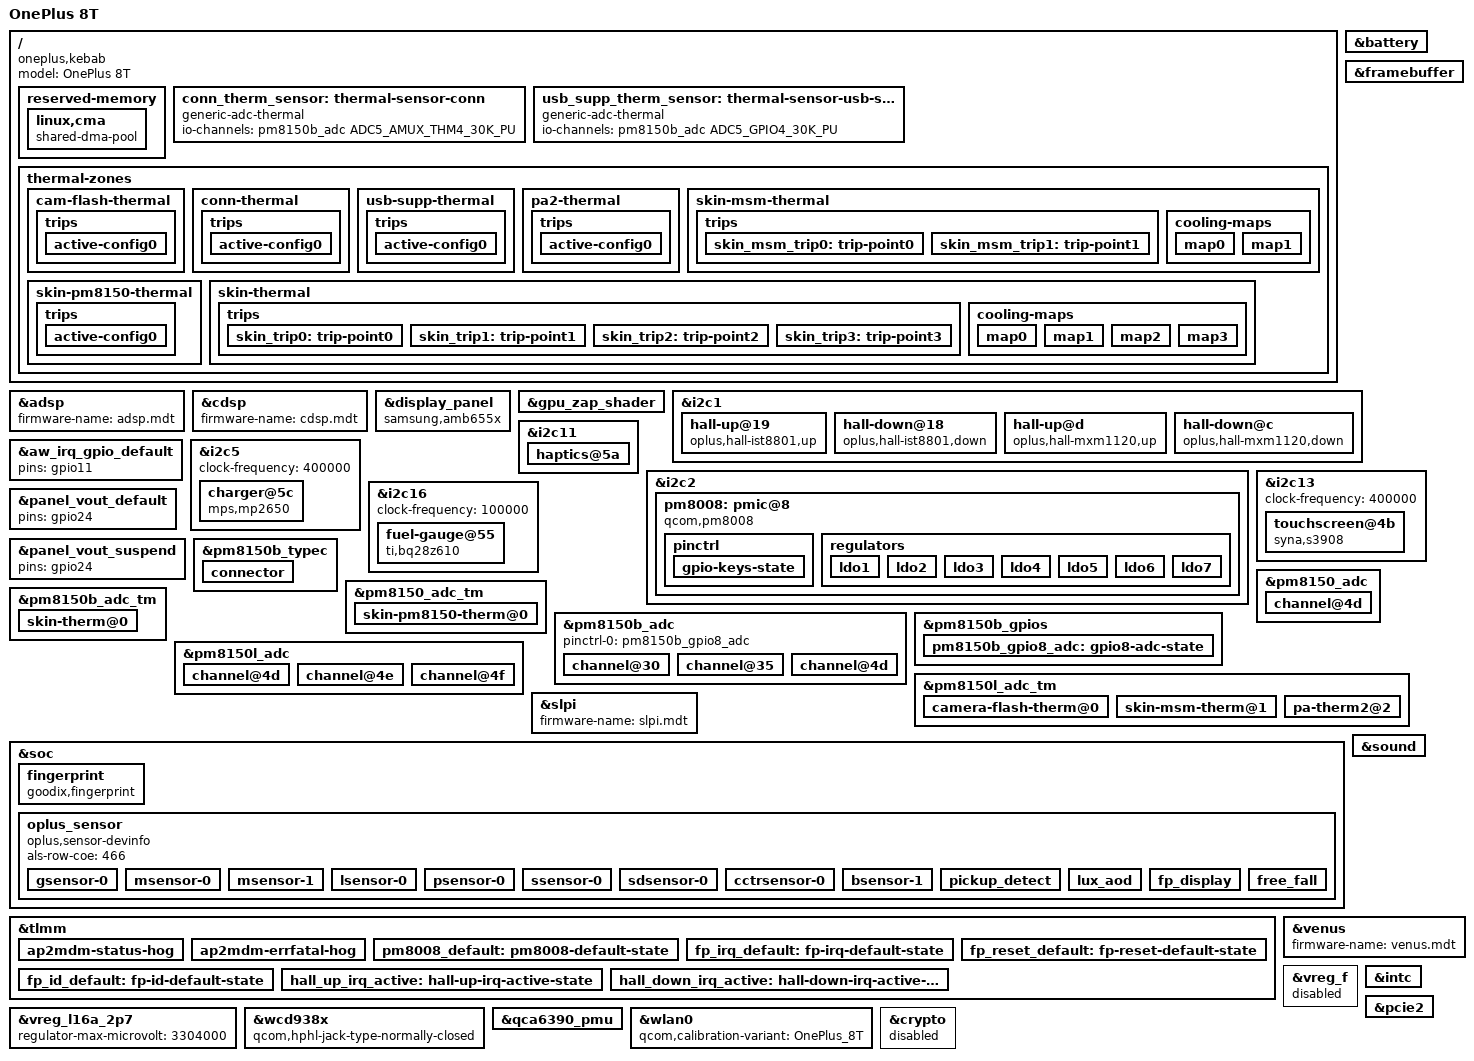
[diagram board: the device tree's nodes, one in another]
// SPDX-License-Identifier: GPL-2.0 OR BSD-3-Clause
/*
 * Copyright (c) 2026, The Linux Foundation.
 */

#include "sm8250-oneplus-common.dtsi"

/ {
	model = "OnePlus 8T";
	compatible = "oneplus,kebab", "qcom,sm8250", "qcom,kona";

	reserved-memory {
		/*
		 * Default CMA area for QTEE trusted app images and shared buffers.
		 * Keep below 4 GiB so legacy 32-bit QSEECom TAs (e.g. Goodix FP)
		 * can embed physical addresses with is64 = 0.
		 */
		linux,cma {
			compatible = "shared-dma-pool";
			alloc-ranges = <0x0 0x80000000 0x0 0x80000000>;
			size = <0x0 0x10000000>;
			reusable;
			linux,cma-default;
		};
	};

	conn_therm_sensor: thermal-sensor-conn {
		compatible = "generic-adc-thermal";
		#thermal-sensor-cells = <0>;
		io-channels = <&pm8150b_adc ADC5_AMUX_THM4_30K_PU>;
		io-channel-names = "sensor-channel";
	};

	usb_supp_therm_sensor: thermal-sensor-usb-supp {
		compatible = "generic-adc-thermal";
		#thermal-sensor-cells = <0>;
		io-channels = <&pm8150b_adc ADC5_GPIO4_30K_PU>;
		io-channel-names = "sensor-channel";
	};

	thermal-zones {
		cam-flash-thermal {
			polling-delay-passive = <0>;
			polling-delay = <0>;
			thermal-sensors = <&pm8150l_adc_tm 0>;

			trips {
				active-config0 {
					temperature = <125000>;
					hysteresis = <1000>;
					type = "passive";
				};
			};
		};

		conn-thermal {
			polling-delay-passive = <0>;
			polling-delay = <0>;
			thermal-sensors = <&conn_therm_sensor>;

			trips {
				active-config0 {
					temperature = <125000>;
					hysteresis = <1000>;
					type = "passive";
				};
			};
		};

		usb-supp-thermal {
			polling-delay-passive = <0>;
			polling-delay = <0>;
			thermal-sensors = <&usb_supp_therm_sensor>;

			trips {
				active-config0 {
					temperature = <125000>;
					hysteresis = <1000>;
					type = "passive";
				};
			};
		};

		pa2-thermal {
			polling-delay-passive = <0>;
			polling-delay = <0>;
			thermal-sensors = <&pm8150l_adc_tm 2>;

			trips {
				active-config0 {
					temperature = <125000>;
					hysteresis = <1000>;
					type = "passive";
				};
			};
		};

		skin-msm-thermal {
			polling-delay-passive = <1000>;
			polling-delay = <0>;
			thermal-sensors = <&pm8150l_adc_tm 1>;

			trips {
				skin_msm_trip0: trip-point0 {
					temperature = <63000>;
					hysteresis = <2000>;
					type = "passive";
				};

				skin_msm_trip1: trip-point1 {
					temperature = <65000>;
					hysteresis = <2000>;
					type = "passive";
				};
			};

			cooling-maps {
				map0 {
					trip = <&skin_msm_trip0>;
					cooling-device = <&gpu 2 2>,
							 <&cpu0 2 2>,
							 <&cpu4 7 7>,
							 <&cpu7 8 8>;
				};

				map1 {
					trip = <&skin_msm_trip1>;
					cooling-device = <&gpu 3 3>,
							 <&cpu0 3 3>,
							 <&cpu4 9 9>,
							 <&cpu7 12 12>;
				};
			};
		};

		skin-pm8150-thermal {
			polling-delay-passive = <0>;
			polling-delay = <0>;
			thermal-sensors = <&pm8150_adc_tm 0>;

			trips {
				active-config0 {
					temperature = <125000>;
					hysteresis = <1000>;
					type = "passive";
				};
			};
		};

		skin-thermal {
			polling-delay-passive = <1000>;
			polling-delay = <0>;
			thermal-sensors = <&pm8150b_adc_tm 0>;

			trips {
				skin_trip0: trip-point0 {
					temperature = <48000>;
					hysteresis = <2000>;
					type = "passive";
				};

				skin_trip1: trip-point1 {
					temperature = <49000>;
					hysteresis = <1000>;
					type = "passive";
				};

				skin_trip2: trip-point2 {
					temperature = <50000>;
					hysteresis = <1000>;
					type = "passive";
				};

				skin_trip3: trip-point3 {
					temperature = <52000>;
					hysteresis = <2000>;
					type = "passive";
				};
			};

			cooling-maps {
				map0 {
					trip = <&skin_trip0>;
					cooling-device = <&gpu 2 2>,
							 <&cpu4 7 7>,
							 <&cpu7 8 8>;
				};

				map1 {
					trip = <&skin_trip1>;
					cooling-device = <&cpu4 9 9>,
							 <&cpu7 11 11>;
				};

				map2 {
					trip = <&skin_trip2>;
					cooling-device = <&gpu 4 4>,
							 <&cpu0 3 3>,
							 <&cpu4 14 14>,
							 <&cpu7 15 15>;
				};

				map3 {
					trip = <&skin_trip3>;
					cooling-device = <&gpu 5 5>,
							 <&cpu0 10 10>,
							 <&cpu4 16 16>,
							 <&cpu7 18 18>;
				};
			};
		};
	};
};

&adsp {
	firmware-name = "adsp.mdt";

	status = "okay";
};

&battery {
	/* Dual-cell 2S pack (2x 2250 mAh in series, 8.70 V max, 19.575 Wh) */
	charge-full-design-microamp-hours = <2250000>;
	energy-full-design-microwatt-hours = <19575000>;
	voltage-max-design-microvolt = <8700000>;
};

&cdsp {
	firmware-name = "cdsp.mdt";

	status = "okay";
};

&display_panel {
	compatible = "samsung,amb655x";

	width-mm = <70>;
	height-mm = <151>;

	status = "okay";
};

&framebuffer {
	width = <1080>;
	height = <2400>;
	stride = <(1080 * 4)>;
};

&gpu_zap_shader {
	firmware-name = "qcom/sm8250/OnePlus/kebab/a650_zap.mbn";
};

&i2c1 {
	/*
	 * Dual-Hall Alert Slider sensors: OnePlus 8T ships with either
	 * iSentek IST8801 (0x19/0x18) or MagnaChip MXM1120 (0x0d/0x0c).
	 * Pinctrl uses the non-default "active" state so only the populated
	 * pair claims the shared IRQ GPIOs after I2C DID verification.
	 */
	hall-up@19 {
		compatible = "oplus,hall-ist8801,up";
		reg = <0x19>;
		vdd-supply = <&vreg_l10c_3p0>;
		interrupts-extended = <&tlmm 157 IRQ_TYPE_LEVEL_LOW>;
		pinctrl-names = "active";
		pinctrl-0 = <&hall_up_irq_active>;
	};

	hall-down@18 {
		compatible = "oplus,hall-ist8801,down";
		reg = <0x18>;
		vdd-supply = <&vreg_l10c_3p0>;
		interrupts-extended = <&tlmm 138 IRQ_TYPE_LEVEL_LOW>;
		pinctrl-names = "active";
		pinctrl-0 = <&hall_down_irq_active>;
	};

	hall-up@d {
		compatible = "oplus,hall-mxm1120,up";
		reg = <0x0d>;
		vdd-supply = <&vreg_l10c_3p0>;
		interrupts-extended = <&tlmm 157 IRQ_TYPE_LEVEL_LOW>;
		pinctrl-names = "active";
		pinctrl-0 = <&hall_up_irq_active>;
	};

	hall-down@c {
		compatible = "oplus,hall-mxm1120,down";
		reg = <0x0c>;
		vdd-supply = <&vreg_l10c_3p0>;
		interrupts-extended = <&tlmm 138 IRQ_TYPE_LEVEL_LOW>;
		pinctrl-names = "active";
		pinctrl-0 = <&hall_down_irq_active>;
	};
};

&i2c11 {
	/* OnePlus 8T routes AW8697 IRQ to TLMM GPIO 11 (8/8 Pro use GPIO 118). */
	haptics@5a {
		interrupts-extended = <&tlmm 11 IRQ_TYPE_EDGE_FALLING>;
	};
};

&aw_irq_gpio_default {
	pins = "gpio11";
};

&i2c2 {
	pm8008: pmic@8 {
		compatible = "qcom,pm8008";
		reg = <0x8>;

		interrupt-parent = <&tlmm>;
		interrupts = <112 IRQ_TYPE_EDGE_RISING>;

		reset-gpios = <&tlmm 93 GPIO_ACTIVE_LOW>;

		vdd-l1-l2-supply = <&vreg_s8c_1p3>;
		vdd-l3-l4-supply = <&vreg_bob>;
		vdd-l5-supply = <&vreg_bob>;
		vdd-l6-supply = <&vreg_bob>;
		vdd-l7-supply = <&vreg_bob>;

		gpio-controller;
		#gpio-cells = <2>;
		gpio-ranges = <&pm8008 0 0 2>;

		interrupt-controller;
		#interrupt-cells = <2>;

		#thermal-sensor-cells = <0>;

		pinctrl {
			gpio-keys-state {
				pins = "gpio1";
				function = "normal";
			};
		};

		regulators {
			ldo1 {
				regulator-name = "vreg_l1p";
				regulator-min-microvolt = <528000>;
				regulator-max-microvolt = <1504000>;
			};

			ldo2 {
				regulator-name = "vreg_l2p";
				regulator-min-microvolt = <528000>;
				regulator-max-microvolt = <1300000>;
			};

			ldo3 {
				regulator-name = "vreg_l3p";
				regulator-min-microvolt = <1500000>;
				regulator-max-microvolt = <3400000>;
			};

			ldo4 {
				regulator-name = "vreg_l4p";
				regulator-min-microvolt = <1800000>;
				regulator-max-microvolt = <1800000>;
			};

			ldo5 {
				regulator-name = "vreg_l5p";
				regulator-min-microvolt = <1500000>;
				regulator-max-microvolt = <3400000>;
			};

			ldo6 {
				regulator-name = "vreg_l6p";
				regulator-min-microvolt = <1500000>;
				regulator-max-microvolt = <3400000>;
			};

			ldo7 {
				regulator-name = "vreg_l7p";
				regulator-min-microvolt = <1500000>;
				regulator-max-microvolt = <3400000>;
			};
		};
	};
};

&i2c5 {
	clock-frequency = <400000>;

	status = "okay";

	charger@5c {
		compatible = "mps,mp2650";
		reg = <0x5c>;
		monitored-battery = <&battery>;
		constant-charge-voltage-max-microvolt = <8700000>;
		constant-charge-current-max-microamp = <3000000>;
		input-current-limit-microamp = <3000000>;
		otg-enable-gpios = <&pm8150_gpios 3 GPIO_ACTIVE_HIGH>;
	};
};

&i2c13 {
	clock-frequency = <400000>;

	status = "okay";

	touchscreen@4b {
		compatible = "syna,s3908";
		reg = <0x4b>;
		interrupts-extended = <&tlmm 39 IRQ_TYPE_LEVEL_LOW>;
		reset-gpios = <&tlmm 38 GPIO_ACTIVE_LOW>;
		vdd-supply = <&vreg_l13a_ts_3p0>;
		vcc-supply = <&vreg_l1c_1p8>;
		touchscreen-size-x = <1080>;
		touchscreen-size-y = <2400>;
		pinctrl-0 = <&ts_int_default>;
		pinctrl-1 = <&ts_rst_suspend>;
		pinctrl-names = "default";
	};
};

&i2c16 {
	/* OOS runs this bus at 100 kHz; 400 kHz NAKs the gauge at 0x55 */
	clock-frequency = <100000>;

	status = "okay";

	fuel-gauge@55 {
		compatible = "ti,bq28z610";
		reg = <0x55>;
		monitored-battery = <&battery>;
	};
};

&panel_vout_default {
	pins = "gpio24";
};

&panel_vout_suspend {
	pins = "gpio24";
};

&pm8150b_typec {
	connector {
		op-sink-microwatt = <27000000>;
		sink-pdos = <PDO_FIXED(5000, 3000,
			     PDO_FIXED_DUAL_ROLE |
			     PDO_FIXED_USB_COMM |
			     PDO_FIXED_DATA_SWAP)>,
			    <PDO_FIXED(9000, 3000, 0)>;
	};
};

&pm8150_adc {
	channel@4d {
		reg = <ADC5_AMUX_THM1_100K_PU>;
		qcom,ratiometric;
		qcom,hw-settle-time = <200>;
		label = "skin_pm8150_therm";
	};
};

&pm8150_adc_tm {
	status = "okay";

	skin-pm8150-therm@0 {
		reg = <0>;
		io-channels = <&pm8150_adc ADC5_AMUX_THM1_100K_PU>;
		qcom,ratiometric;
		qcom,hw-settle-time-us = <200>;
	};
};

&pm8150b_adc {
	pinctrl-0 = <&pm8150b_gpio8_adc>;
	pinctrl-names = "default";

	channel@30 {
		reg = <ADC5_AMUX_THM4_30K_PU>;
		qcom,ratiometric;
		qcom,hw-settle-time = <700>;
		label = "usb_temp_adc";
	};

	channel@35 {
		reg = <ADC5_GPIO4_30K_PU>;
		qcom,ratiometric;
		qcom,hw-settle-time = <700>;
		label = "usb_supp_temp_adc";
	};

	channel@4d {
		reg = <ADC5_AMUX_THM1_100K_PU>;
		qcom,ratiometric;
		qcom,hw-settle-time = <200>;
		label = "skin_therm";
	};
};

&pm8150b_adc_tm {
	status = "okay";

	skin-therm@0 {
		reg = <0>;
		io-channels = <&pm8150b_adc ADC5_AMUX_THM1_100K_PU>;
		qcom,ratiometric;
		qcom,hw-settle-time-us = <200>;
	};
};

&pm8150b_gpios {
	pm8150b_gpio8_adc: gpio8-adc-state {
		pins = "gpio8";
		function = "normal";
		bias-high-impedance;
	};
};

&pm8150l_adc {
	channel@4d {
		reg = <ADC5_AMUX_THM1_100K_PU>;
		qcom,ratiometric;
		qcom,hw-settle-time = <200>;
		label = "camera_flash_therm";
	};

	channel@4e {
		reg = <ADC5_AMUX_THM2_100K_PU>;
		qcom,ratiometric;
		qcom,hw-settle-time = <200>;
		label = "skin_msm_therm";
	};

	channel@4f {
		reg = <ADC5_AMUX_THM3_100K_PU>;
		qcom,ratiometric;
		qcom,hw-settle-time = <200>;
		label = "pa_therm2";
	};
};

&pm8150l_adc_tm {
	status = "okay";

	camera-flash-therm@0 {
		reg = <0>;
		io-channels = <&pm8150l_adc ADC5_AMUX_THM1_100K_PU>;
		qcom,ratiometric;
		qcom,hw-settle-time-us = <200>;
	};

	skin-msm-therm@1 {
		reg = <1>;
		io-channels = <&pm8150l_adc ADC5_AMUX_THM2_100K_PU>;
		qcom,ratiometric;
		qcom,hw-settle-time-us = <200>;
	};

	pa-therm2@2 {
		reg = <2>;
		io-channels = <&pm8150l_adc ADC5_AMUX_THM3_100K_PU>;
		qcom,ratiometric;
		qcom,hw-settle-time-us = <200>;
	};
};

&slpi {
	firmware-name = "slpi.mdt";

	status = "okay";
};

&soc {
	fingerprint {
		compatible = "goodix,fingerprint";
		fp-gpio-irq = <&tlmm 23 GPIO_ACTIVE_HIGH>;
		fp-gpio-reset = <&tlmm 68 GPIO_ACTIVE_HIGH>;
		fp-gpio-id = <&tlmm 77 GPIO_ACTIVE_HIGH>;
		vdd-supply = <&vreg_l16a_2p7>;
		vdd-min-uv = <3304000>;
		vdd-max-uv = <3304000>;
		pinctrl-0 = <&fp_irq_default>, <&fp_reset_default>, <&fp_id_default>;
		pinctrl-names = "default";
	};

	oplus_sensor {
		compatible = "oplus,sensor-devinfo";
		als-row-coe = <466>;

		gsensor-0 {
			sensor-name = <0x8>; /* BMI260 */
			sensor-direction = <4>;
			sensor-index = <0>;
			sensor-type = <0>; /* OPLUS_ACCEL */
		};

		msensor-0 {
			sensor-name = <0x1>; /* AKM0991X */
			sensor-direction = <4>;
			sensor-index = <0>;
			sensor-type = <2>; /* OPLUS_MAG */
			parameter-number = <18>;
			soft-mag-parameter = <10000 0 0 0 0 0 0 0 10000 0 0 0 0 0 0 0 10000 0>;
		};

		msensor-1 {
			sensor-name = <0x2>; /* MMC5603 */
			sensor-direction = <1>;
			sensor-index = <1>;
			sensor-type = <2>; /* OPLUS_MAG */
			parameter-number = <18>;
			soft-mag-parameter = <9941 0 1024 0 356 0 137 0 9375 0 608 0 102 0 495 0 11471 0>;
		};

		lsensor-0 {
			sensor-name = <0x01>; /* STK33502 */
			sensor-index = <0>;
			sensor-type = <3>; /* OPLUS_LIGHT */
			bus-number = <5>;
			irq-number = <136>;
			als-type = <2>;
			is-unit-device = <1>;
			is-als-dri = <0>;
			als-factor = <466>;
			is_als_initialed = <0>;
			als_buffer_length = <10>;
		};

		psensor-0 {
			sensor-name = <0x1>; /* STK33502 */
			sensor-index = <0>;
			sensor-type = <4>; /* OPLUS_PROXIMITY */
			bus-number = <5>;
			irq-number = <136>;
			ps-type = <1>;
			ps_saturation = <2600>;
			is_need_close_pd = <0>;
			parameter-number = <4>;
			sensor-reg = <0x01 0x32 0x03 0x80 0xDB 0x00>;
		};

		ssensor-0 {
			sensor-name = <0x1>; /* SX9324 */
			sensor-index = <0>;
			sensor-type = <5>; /* OPLUS_SAR */
			parameter-number = <18>;
			sensor-reg = <0x10 0x16 0x24 0x5F 0x26 0x00 0x27 0x5F
				      0x28 0x37 0x29 0x1F 0x2A 0x3D 0x36 0x24
				      0x37 0x24>;
		};

		sdsensor-0 {
			sensor-name = <0x1>; /* SX9324 */
			sensor-index = <0>;
			sensor-type = <9>; /* OPLUS_SARS */
			parameter-number = <18>;
			sensor-reg = <0x23 0x00 0x24 0x5F 0x26 0x00 0x27 0x5F
				      0x28 0x3D 0x29 0x1F 0x2A 0x37 0x36 0x32
				      0x37 0x24>;
		};

		cctrsensor-0 {
			decoupled-driver = <0>;
			sensor-name = <0x1>; /* TCS3408 */
			sensor-index = <0>;
			sensor-type = <7>; /* OPLUS_CCT_REAR */
			para-matrix = <4>;
		};

		bsensor-1 {
			sensor-name = <0x2>; /* BMP380 */
			sensor-index = <0>;
			sensor-type = <8>; /* OPLUS_BAROMETER */
		};

		pickup_detect {
			sensor-type = <0>;
			is-virtual-sensor;
			is-need-prox = <1>;
			prox-type = <0>;
		};

		lux_aod {
			sensor-type = <1>;
			is-virtual-sensor;
			thrd-low = <12>;
			thrd-high = <50>;
			als-type = <1>;
		};

		fp_display {
			sensor-type = <3>;
			is-virtual-sensor;
			prox-type = <0>;
		};

		free_fall {
			sensor-type = <4>;
			is-virtual-sensor;
		};
	};
};

&tlmm {
	/*
	 * External SDX55 handshake (downstream esoc mdm0): tell the modem the
	 * AP is up and has not crashed, as the esoc driver does at power-on.
	 */
	ap2mdm-status-hog {
		gpio-hog;
		gpios = <56 GPIO_ACTIVE_HIGH>;
		output-high;
		line-name = "ap2mdm-status";
	};

	ap2mdm-errfatal-hog {
		gpio-hog;
		gpios = <57 GPIO_ACTIVE_HIGH>;
		output-low;
		line-name = "ap2mdm-errfatal";
	};

	pm8008_default: pm8008-default-state {
		pins = "gpio93";
		function = "gpio";
		bias-pull-up;
		output-high;
		drive-strength = <2>;
	};

	fp_irq_default: fp-irq-default-state {
		pins = "gpio23";
		function = "gpio";
		drive-strength = <2>;
		bias-pull-down;
	};

	fp_reset_default: fp-reset-default-state {
		pins = "gpio68";
		function = "gpio";
		drive-strength = <2>;
		bias-disable;
	};

	fp_id_default: fp-id-default-state {
		pins = "gpio77";
		function = "gpio";
		drive-strength = <2>;
		bias-disable;
	};

	hall_up_irq_active: hall-up-irq-active-state {
		pins = "gpio157";
		function = "gpio";
		drive-strength = <2>;
		input-enable;
		bias-pull-up;
	};

	hall_down_irq_active: hall-down-irq-active-state {
		pins = "gpio138";
		function = "gpio";
		drive-strength = <2>;
		input-enable;
		bias-pull-up;
	};
};

&sound {
	model = "OnePlus-8T";
	audio-routing =
		"AMIC2", "MIC BIAS2",
		"TX DMIC0", "MIC BIAS1",
		"TX DMIC1", "MIC BIAS1",
		"TX DMIC2", "MIC BIAS4",
		"TX DMIC3", "MIC BIAS3",
		"TX DMIC4", "MIC BIAS4",
		"TX DMIC5", "MIC BIAS4",
		"DMIC1", "MIC BIAS1",
		"DMIC2", "MIC BIAS1",
		"DMIC3", "MIC BIAS3",
		"DMIC4", "MIC BIAS3",
		"DMIC5", "MIC BIAS4",
		"DMIC6", "MIC BIAS4",
		"IN1_HPHL", "HPHL_OUT",
		"IN2_HPHR", "HPHR_OUT",
		"IN3_AUX", "AUX_OUT",
		"TX SWR_ADC0", "ADC1_OUTPUT",
		"TX SWR_ADC1", "ADC2_OUTPUT",
		"TX SWR_ADC2", "ADC3_OUTPUT",
		"TX SWR_ADC3", "ADC4_OUTPUT",
		"TX SWR_DMIC0", "DMIC1_OUTPUT",
		"TX SWR_DMIC1", "DMIC2_OUTPUT",
		"TX SWR_DMIC2", "DMIC3_OUTPUT",
		"TX SWR_DMIC3", "DMIC4_OUTPUT",
		"TX SWR_DMIC4", "DMIC5_OUTPUT",
		"TX SWR_DMIC5", "DMIC6_OUTPUT",
		"TX SWR_DMIC6", "DMIC7_OUTPUT",
		"TX SWR_DMIC7", "DMIC8_OUTPUT",
		"RX_TX DEC0_INP", "TX DEC0 MUX",
		"RX_TX DEC1_INP", "TX DEC1 MUX",
		"RX_TX DEC2_INP", "TX DEC2 MUX",
		"RX_TX DEC3_INP", "TX DEC3 MUX",
		"VA DMIC0", "VA MIC BIAS3",
		"VA DMIC1", "VA MIC BIAS1",
		"VA DMIC2", "VA MIC BIAS1",
		"VA DMIC3", "VA MIC BIAS3",
		"VA DMIC4", "VA MIC BIAS4",
		"VA DMIC5", "VA MIC BIAS4",
		"VA SWR_ADC0", "ADC1_OUTPUT",
		"VA SWR_ADC1", "ADC2_OUTPUT",
		"VA SWR_ADC2", "ADC3_OUTPUT",
		"VA SWR_ADC3", "ADC4_OUTPUT",
		"VA SWR_MIC0", "DMIC1_OUTPUT",
		"VA SWR_MIC1", "DMIC2_OUTPUT",
		"VA SWR_MIC2", "DMIC3_OUTPUT",
		"VA SWR_MIC3", "DMIC4_OUTPUT",
		"VA SWR_MIC4", "DMIC5_OUTPUT",
		"VA SWR_MIC5", "DMIC6_OUTPUT",
		"VA SWR_MIC6", "DMIC7_OUTPUT",
		"VA SWR_MIC7", "DMIC8_OUTPUT";

	/delete-node/ usb-dai-link;
};

&venus {
	firmware-name = "venus.mdt";

	status = "okay";
};

&vreg_f {
	status = "disabled";
};

/* Optical fingerprint sensor supply (stock drives pm8150_l16 at 3.3V) */
&vreg_l16a_2p7 {
	regulator-max-microvolt = <3304000>;
};

&wcd938x {
	qcom,hphl-jack-type-normally-closed;
};

&qca6390_pmu {
	vddpmu-supply = <&vreg_s6a_0p95>;
	vddrfa0p95-supply = <&vreg_s6a_0p95>;
	qcom,calibration-variant = "OnePlus_8T";
};

&wlan0 {
	qcom,calibration-variant = "OnePlus_8T";
};

/*
 * Expose GICv3 MBI on SM8250's dedicated PCIe2 MSI SPIs (GIC_SPI 832..863 ->
 * hwirq 864..895, GICD_SETSPI_NSR alias 0x17a10040), matching stock kona-pcie.
 */
&intc {
	msi-controller;
	mbi-alias = <0x0 0x17a10000>;
	mbi-ranges = <864 32>;
};

/* X55 handshake lines, as on Sony edo (same SM8250 + SDX55 wiring) */
&pcie2 {
	pinctrl-0 = <&pcie2_default_state &ap2mdm_active>;
	/* Stock kona-pcie.dtsi configures WAKE# (gpio87) active-low with pull-up */
	wake-gpios = <&tlmm 87 GPIO_ACTIVE_LOW>;
	msi-parent = <&intc>;
};

/*
 * QCE hardware crypto driver (CONFIG_CRYPTO_DEV_QCE) is not used on kebab
 * (ARMv8 CE and UFS ICE handle crypto); disable the node so its interconnect
 * suppliers (aggre2_noc, mc_virt) are not blocked from running icc_sync_state().
 */
&crypto {
	status = "disabled";
};
